# GD32E230 register map
File version: 1.0
CPU: CM23 r0p0, little endian, MPU, FPU, 4 interrupt priority bits
Registers are 32-bit, read-write, reset 0x0 unless marked. A register's access mark holds for its fields unless they carry their own. Offsets are from the block's base; [hi:lo] are bit positions; {n}, {i} and the like mark numbered series.

## CRC — cyclic redundancy check calculation unit
Base 0x40023000
0x00 DATA reset 0xFFFFFFFF
  [31:0] DATA — CRC calculation result bits
0x04 FDATA — Free data register
  [7:0] FDATA — General-purpose 8-bit data register bits
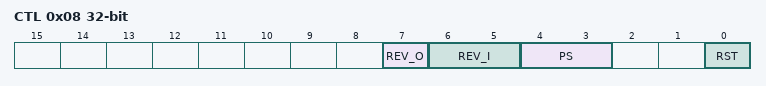
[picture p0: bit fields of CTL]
0x08 CTL — Control register
  [7] REV_O — Reverse output data
  [6:5] REV_I — Reverse input data
  [4:3] PS — Size of polynomial
  [0] RST — reset bit
0x10 IDATA reset 0xFFFFFFFF — Initialization Data Register
  [31:0] IDATA — CRC calculation initial value
0x14 POLY reset 0x4C11DB7 — Polynomial register
  [31:0] POLY — User configurable polynomial value

## DBGMCU — Debug support
Base 0x40015800
0x00 ID ro — MCU Device ID Code Register
  [31:0] ID_CODE — DBG ID code register
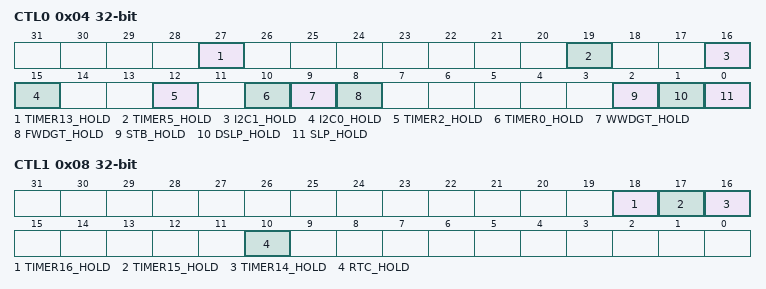
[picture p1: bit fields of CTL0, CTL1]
0x04 CTL0 — Debug Control Register 0
  [27] TIMER13_HOLD
  [19] TIMER5_HOLD
  [16] I2C1_HOLD
  [15] I2C0_HOLD
  [12] TIMER2_HOLD
  [10] TIMER0_HOLD
  [9] WWDGT_HOLD
  [8] FWDGT_HOLD
  [2] STB_HOLD — Standby mode hold Mode
  [1] DSLP_HOLD — DEEPSLEEP mode hold Mode
  [0] SLP_HOLD — Sleep mode hold register
0x08 CTL1 — Debug Control Register 1
  [18] TIMER16_HOLD, [17] TIMER15_HOLD, [16] TIMER14_HOLD, [10] RTC_HOLD

## DMA — DMA controller
Base 0x40020000
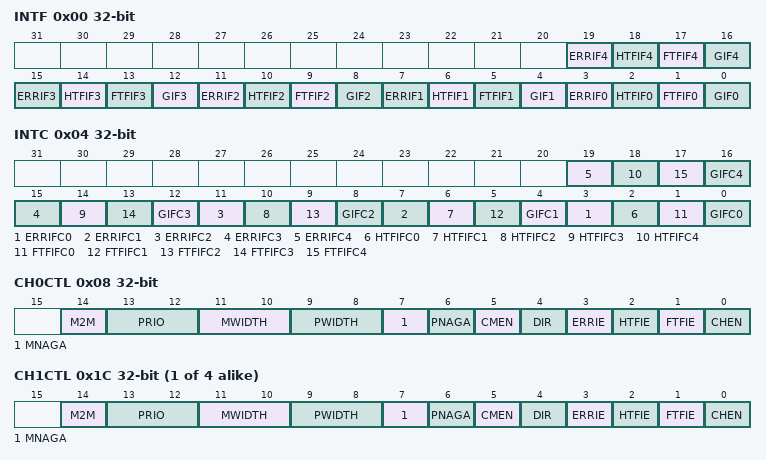
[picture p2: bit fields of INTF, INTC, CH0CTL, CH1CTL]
0x00 INTF ro — DMA interrupt flag register (DMA_INTF)
  [4n+3] ERRIF{n} (n=0..4) — Channel {n} Error flag
  [4n+2] HTFIF{n} (n=0..4) — Channel {n} Half Transfer Finish flag
  [4n+1] FTFIF{n} (n=0..4) — Channel {n} Full Transfer Finish flag
  [4n] GIF{n} (n=0..4) — Channel {n} Global interrupt flag
0x04 INTC wo — DMA interrupt flag clear register (DMA_INTC)
  [4n+3] ERRIFC{n} (n=0..4) — Channel {n} Error clear
  [4n+2] HTFIFC{n} (n=0..4) — Channel {n} Half Transfer clear
  [4n+1] FTFIFC{n} (n=0..4) — Channel {n} Full Transfer Finish clear
  [4n] GIFC{n} (n=0..4) — Channel {n} Global interrupt flag clear
0x08 CH0CTL — DMA channel configuration register (DMA_CH0CTL)
  [14] M2M — Memory to memory mode
  [13:12] PRIO — Priority Level of this channel
  [11:10] MWIDTH — Transfer data size of memory
  [9:8] PWIDTH — Transfer data size of peripheral
  [7] MNAGA — Next address generation algorithm of memory
  [6] PNAGA — Next address generation algorithm of peripheral
  [5] CMEN — Circular mode enable
  [4] DIR — Transfer direction
  [3] ERRIE — Transfer access error interrupt enable
  [2] HTFIE — Half Transfer Finish interrupt enable
  [1] FTFIE — Full Transfer Finish interrupt enable
  [0] CHEN — Channel enable
{0xC+0x14*i} CH{i}CNT (i=0..4) — DMA channel {i} counter register
  [15:0] CNT — Transfer counter
{0x10+0x14*i} CH{i}PADDR (i=0..4) — DMA channel {i} peripheral base address register
  [31:0] PADDR — Peripheral base address
{0x14+0x14*i} CH{i}MADDR (i=0..4) — DMA channel {i} memory base address register
  [31:0] MADDR — Memory address
{0x8+0x14*i} CH{i}CTL (i=1..4) — DMA channel configuration register (DMA_CH{i}CTL)
  [14] M2M — Memory to memory mode
  [13:12] PRIO — Priority Level of this channel
  [11:10] MWIDTH — Transfer data size of memory
  [9:8] PWIDTH — Transfer data size of peripheral
  [7] MNAGA — Next address generation algorithm of memory
  [6] PNAGA — Next address generation algorithm of peripheral
  [5] CMEN — Circular mode enable
  [4] DIR — Transfer direction
  [3] ERRIE — Error interrupt enable
  [2] HTFIE — Half Transfer Finish interrupt enable
  [1] FTFIE — Full Transfer Finish interrupt enable
  [0] CHEN — Channel enable

## EXTI — External interrupt/event controller
Base 0x40010400
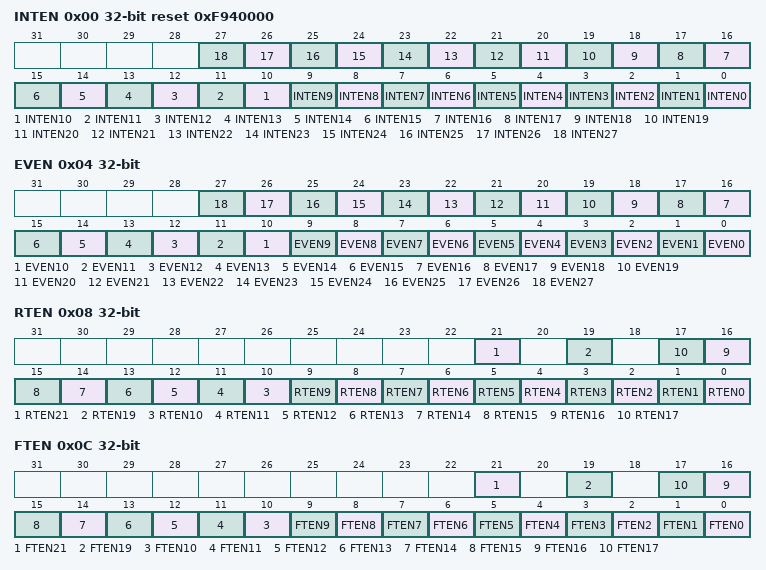
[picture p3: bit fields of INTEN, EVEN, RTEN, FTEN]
0x00 INTEN reset 0xF940000 — Interrupt enable register (EXTI_INTEN)
  [n] INTEN{n} (n=0..27) — Enable Interrupt on line {n}
0x04 EVEN — Event enable register (EXTI_EVEN)
  [n] EVEN{n} (n=0..27) — Enable Event on line {n}
0x08 RTEN — Rising Edge Trigger Enable register (EXTI_RTEN)
  [21] RTEN21 — Rising trigger event configuration of line 21
  [19] RTEN19 — Rising trigger event configuration of line 19
  [n] RTEN{n} (n=0..17) — Rising trigger event configuration of line {n}
0x0C FTEN — Falling Egde Trigger Enable register (EXTI_FTEN)
  [21] FTEN21 — Falling trigger event configuration of line 21
  [19] FTEN19 — Falling trigger event configuration of line 19
  [n] FTEN{n} (n=0..17) — Falling trigger event configuration of line {n}
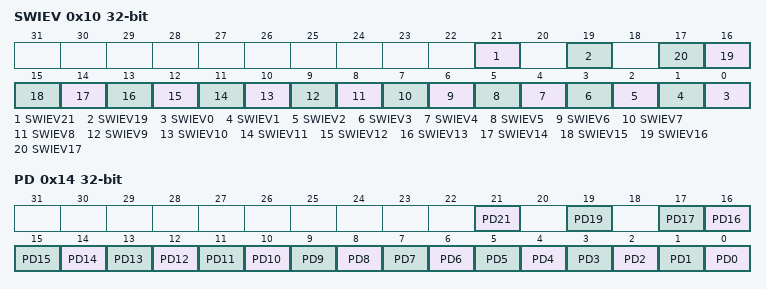
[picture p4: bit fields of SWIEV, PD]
0x10 SWIEV — Software interrupt event register (EXTI_SWIEV)
  [21] SWIEV21 — Software Interrupt on line 21
  [19] SWIEV19 — Software Interrupt on line 19
  [n] SWIEV{n} (n=0..17) — Software Interrupt on line {n}
0x14 PD — Pending register (EXTI_PD)
  [21] PD21 — Pending bit 21
  [19] PD19 — Pending bit 19
  [n] PD{n} (n=0..17) — Pending bit {n}
